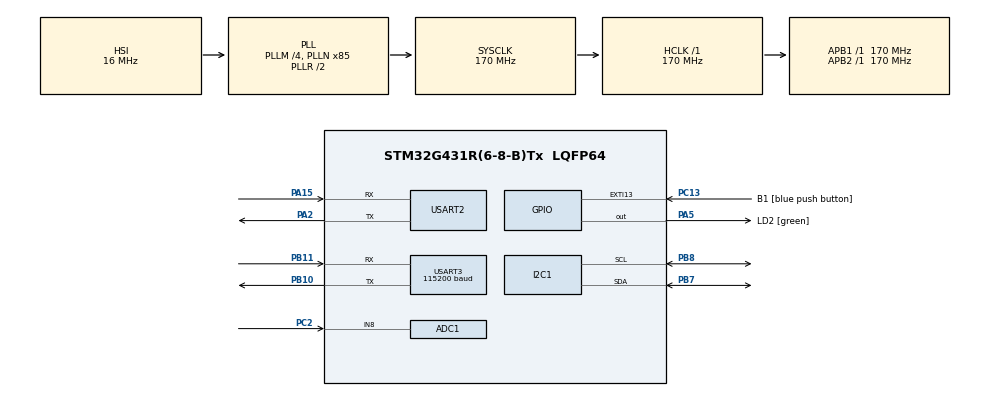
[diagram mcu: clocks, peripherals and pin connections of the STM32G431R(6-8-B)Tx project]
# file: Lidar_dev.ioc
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ADC1.Channel-1\#ChannelRegularConversion=ADC_CHANNEL_8
ADC1.ContinuousConvMode=ENABLE
ADC1.DMAContinuousRequests=ENABLE
ADC1.EnableAnalogWatchDog1=false
ADC1.ExternalTrigConv=ADC_EXTERNALTRIG_T6_TRGO
ADC1.NbrOfConversionFlag=1
ADC1.OffsetNumber-1\#ChannelRegularConversion=ADC_OFFSET_NONE
ADC1.Rank-1\#ChannelRegularConversion=1
ADC1.SamplingTime-1\#ChannelRegularConversion=ADC_SAMPLETIME_47CYCLES_5
ADC1.master=1
Dma.ADC1.0.Direction=DMA_PERIPH_TO_MEMORY
Dma.ADC1.0.EventEnable=DISABLE
Dma.ADC1.0.Instance=DMA1_Channel1
Dma.ADC1.0.MemDataAlignment=DMA_MDATAALIGN_WORD
Dma.ADC1.0.MemInc=DMA_MINC_ENABLE
Dma.ADC1.0.Mode=DMA_CIRCULAR
Dma.ADC1.0.PeriphDataAlignment=DMA_PDATAALIGN_HALFWORD
Dma.ADC1.0.PeriphInc=DMA_PINC_DISABLE
Dma.ADC1.0.Polarity=HAL_DMAMUX_REQ_GEN_RISING
Dma.ADC1.0.Priority=DMA_PRIORITY_LOW
Dma.ADC1.0.RequestNumber=1
Dma.ADC1.0.SignalID=NONE
Dma.ADC1.0.SyncEnable=DISABLE
Dma.ADC1.0.SyncPolarity=HAL_DMAMUX_SYNC_NO_EVENT
Dma.ADC1.0.SyncRequestNumber=1
Dma.ADC1.0.SyncSignalID=NONE
Dma.Request0=ADC1
I2C1.Timing=0x40B285C2
Mcu.Family=STM32G4
Mcu.Name=STM32G431R(6-8-B)Tx
Mcu.Package=LQFP64
NVIC.DMA1_Channel1_IRQn=true\:0\:0\:false\:false\:true\:false\:true\:true
NVIC.PriorityGroup=NVIC_PRIORITYGROUP_4
NVIC.TIM1_BRK_TIM15_IRQn=true\:0\:0\:false\:false\:true\:true\:true\:true
NVIC.TIM1_CC_IRQn=true\:0\:0\:false\:false\:true\:true\:true\:true
NVIC.TIM1_TRG_COM_TIM17_IRQn=true\:0\:0\:false\:false\:true\:true\:true\:true
NVIC.TIM1_UP_TIM16_IRQn=true\:0\:0\:false\:false\:true\:true\:true\:true
NVIC.USART3_IRQn=true\:0\:0\:false\:false\:true\:true\:true\:true
PA13.GPIO_Label=T_SWDIO
PA13.Signal=SYS_JTMS-SWDIO
PA14.GPIO_Label=T_SWCLK
PA14.Signal=SYS_JTCK-SWCLK
PA15.Mode=Asynchronous
PA15.Signal=USART2_RX
PA2.Mode=Asynchronous
PA2.Signal=USART2_TX
PA3.GPIO_Label=LPUART1_RX [STLINKV3E_VCP_TX]
PA3.Signal=LPUART1_RX
PA5.GPIO_Label=LD2 [green]
PA5.Signal=GPIO_Output
PB10.Mode=Asynchronous
PB10.Signal=USART3_TX
PB11.Mode=Asynchronous
PB11.Signal=USART3_RX
PB3.GPIO_Label=T_SWO
PB3.Signal=SYS_JTDO-SWO
PB7.Mode=I2C
PB7.Signal=I2C1_SDA
PB8-BOOT0.Mode=I2C
PB8-BOOT0.Signal=I2C1_SCL
PC13.GPIO_Label=B1 [blue push button]
PC13.Signal=GPXTI13
PC14-OSC32_IN.GPIO_Label=RCC_OSC32_OUT
PC14-OSC32_IN.Signal=RCC_OSC32_IN
PC15-OSC32_OUT.GPIO_Label=RCC_OSC32_OUT
PC15-OSC32_OUT.Signal=RCC_OSC32_OUT
PC2.Mode=IN8-Single-Ended
PC2.Signal=ADC1_IN8
PF0-OSC_IN.GPIO_Label=RCC_OSC_IN
PF0-OSC_IN.Signal=RCC_OSC_IN
PF1-OSC_OUT.GPIO_Label=RCC_OSC_OUT
PF1-OSC_OUT.Signal=RCC_OSC_OUT
ProjectManager.HeapSize=0x200
ProjectManager.StackSize=0x400
ProjectManager.TargetToolchain=STM32CubeIDE
RCC.ADC12Freq_Value=170000000
RCC.AHBFreq_Value=170000000
RCC.APB1Freq_Value=170000000
RCC.APB1TimFreq_Value=170000000
RCC.APB2Freq_Value=170000000
RCC.APB2TimFreq_Value=170000000
RCC.CortexFreq_Value=170000000
RCC.EXTERNAL_CLOCK_VALUE=12288000
RCC.HCLKFreq_Value=170000000
RCC.HSE_VALUE=24000000
RCC.HSI48_VALUE=48000000
RCC.HSI_VALUE=16000000
RCC.LSE_VALUE=32768
RCC.PLLM=RCC_PLLM_DIV4
RCC.PLLN=85
RCC.RTCClockSelection=RCC_RTCCLKSOURCE_LSE
RCC.SYSCLKFreq_VALUE=170000000
RCC.SYSCLKSource=RCC_SYSCLKSOURCE_PLLCLK
RCC.USBFreq_Value=170000000
RCC.VCOOutputFreq_Value=340000000
TIM1.PeriodNoDither=1700-1
TIM1.Prescaler=5-1
TIM1.TIM_MasterOutputTrigger=TIM_TRGO_UPDATE
TIM2.Prescaler=15999
TIM2.TIM_MasterOutputTrigger=TIM_TRGO_UPDATE
TIM2.TIM_MasterSlaveMode=TIM_MASTERSLAVEMODE_ENABLE
TIM6.PeriodNoDither=9999
TIM6.Prescaler=16999
TIM6.TIM_MasterOutputTrigger=TIM_TRGO_UPDATE
USART2.VirtualMode-Asynchronous=VM_ASYNC
USART3.BaudRate=115200
USART3.Mode=MODE_RX
USART3.VirtualMode-Asynchronous=VM_ASYNC
VP_SYS_VS_DBSignals.Mode=DisableDeadBatterySignals
VP_TIM16_VS_ClockSourceINT.Mode=Enable_Timer
VP_TIM1_VS_ClockSourceINT.Mode=Internal
VP_TIM2_VS_ClockSourceINT.Mode=Internal
VP_TIM6_VS_ClockSourceINT.Mode=Enable_Timer
board=NUCLEO-G431RB

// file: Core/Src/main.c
/* USER CODE BEGIN Header */
/**
 ******************************************************************************
 * @file           : main.c
 * @brief          : Main program body
 ******************************************************************************
 * @attention
 *
 * Copyright (c) 2024 STMicroelectronics.
 * All rights reserved.
 *
 * This software is licensed under terms that can be found in the LICENSE file
 * in the root directory of this software component.
 * If no LICENSE file comes with this software, it is provided AS-IS.
 *
 ******************************************************************************
 */
/* USER CODE END Header */
#include "main.h"
#include "adc.h"
#include "dma.h"
#include "i2c.h"
#include "tim.h"
#include "usart.h"
#include "gpio.h"

/* USER CODE BEGIN Includes */

#include <stdio.h>
#include <stdlib.h>
#include <string.h>

#include "lidar_X2_driver.h"

/* USER CODE END Includes */

/* USER CODE BEGIN PV */

extern uint8_t LidarUartFlag;
extern UART_HandleTypeDef huart3;

HAL_StatusTypeDef status;

/* USER CODE END PV */

void SystemClock_Config(void);

int main(void)
{

	/* MCU Configuration--------------------------------------------------------*/

	/* Reset of all peripherals, Initializes the Flash interface and the Systick. */
	HAL_Init();

	/* Configure the system clock */
	SystemClock_Config();

	/* Initialize all configured peripherals */
	MX_GPIO_Init();
	MX_DMA_Init();
	MX_USART2_UART_Init();
	MX_USART3_UART_Init();
	MX_I2C1_Init();
	MX_ADC1_Init();
	MX_TIM2_Init();
	MX_TIM6_Init();
	MX_TIM16_Init();
	MX_TIM1_Init();
	/* USER CODE BEGIN 2 */

	printf("Starting DMA... \r\n");

	lidar_init();
	/*
	while (!lidar_initialized)
	{
		lidar_initialized = init_lidar();
		printf("lidar init code: %i \r\n", lidar_initialized);
	}
	printf("FullyInit\r\n");

	 */

	/* USER CODE END 2 */

	/* Infinite loop */
	/* USER CODE BEGIN WHILE */
	while (1)
	{
		lidar_scan_loop();

	}
	/* USER CODE END WHILE */

}

void SystemClock_Config(void)
{
	RCC_OscInitTypeDef RCC_OscInitStruct = {0};
	RCC_ClkInitTypeDef RCC_ClkInitStruct = {0};

	/** Configure the main internal regulator output voltage
	 */
	HAL_PWREx_ControlVoltageScaling(PWR_REGULATOR_VOLTAGE_SCALE1_BOOST);

	/** Initializes the RCC Oscillators according to the specified parameters
	 * in the RCC_OscInitTypeDef structure.
	 */
	RCC_OscInitStruct.OscillatorType = RCC_OSCILLATORTYPE_HSI;
	RCC_OscInitStruct.HSIState = RCC_HSI_ON;
	RCC_OscInitStruct.HSICalibrationValue = RCC_HSICALIBRATION_DEFAULT;
	RCC_OscInitStruct.PLL.PLLState = RCC_PLL_ON;
	RCC_OscInitStruct.PLL.PLLSource = RCC_PLLSOURCE_HSI;
	RCC_OscInitStruct.PLL.PLLM = RCC_PLLM_DIV4;
	RCC_OscInitStruct.PLL.PLLN = 85;
	RCC_OscInitStruct.PLL.PLLP = RCC_PLLP_DIV2;
	RCC_OscInitStruct.PLL.PLLQ = RCC_PLLQ_DIV2;
	RCC_OscInitStruct.PLL.PLLR = RCC_PLLR_DIV2;
	if (HAL_RCC_OscConfig(&RCC_OscInitStruct) != HAL_OK)
	{
		Error_Handler();
	}

	/** Initializes the CPU, AHB and APB buses clocks
	 */
	RCC_ClkInitStruct.ClockType = RCC_CLOCKTYPE_HCLK|RCC_CLOCKTYPE_SYSCLK
			|RCC_CLOCKTYPE_PCLK1|RCC_CLOCKTYPE_PCLK2;
	RCC_ClkInitStruct.SYSCLKSource = RCC_SYSCLKSOURCE_PLLCLK;
	RCC_ClkInitStruct.AHBCLKDivider = RCC_SYSCLK_DIV1;
	RCC_ClkInitStruct.APB1CLKDivider = RCC_HCLK_DIV1;
	RCC_ClkInitStruct.APB2CLKDivider = RCC_HCLK_DIV1;

	if (HAL_RCC_ClockConfig(&RCC_ClkInitStruct, FLASH_LATENCY_4) != HAL_OK)
	{
		Error_Handler();
	}
}

/* USER CODE BEGIN 4 */

void HAL_ADC_ConvCpltCallback(ADC_HandleTypeDef* hadc)
{
	if(hadc->Instance == ADC1)
	{

	}
}

/* USER CODE END 4 */

void Error_Handler(void)
{
	__disable_irq();
	while (1)
	{
	}
}
